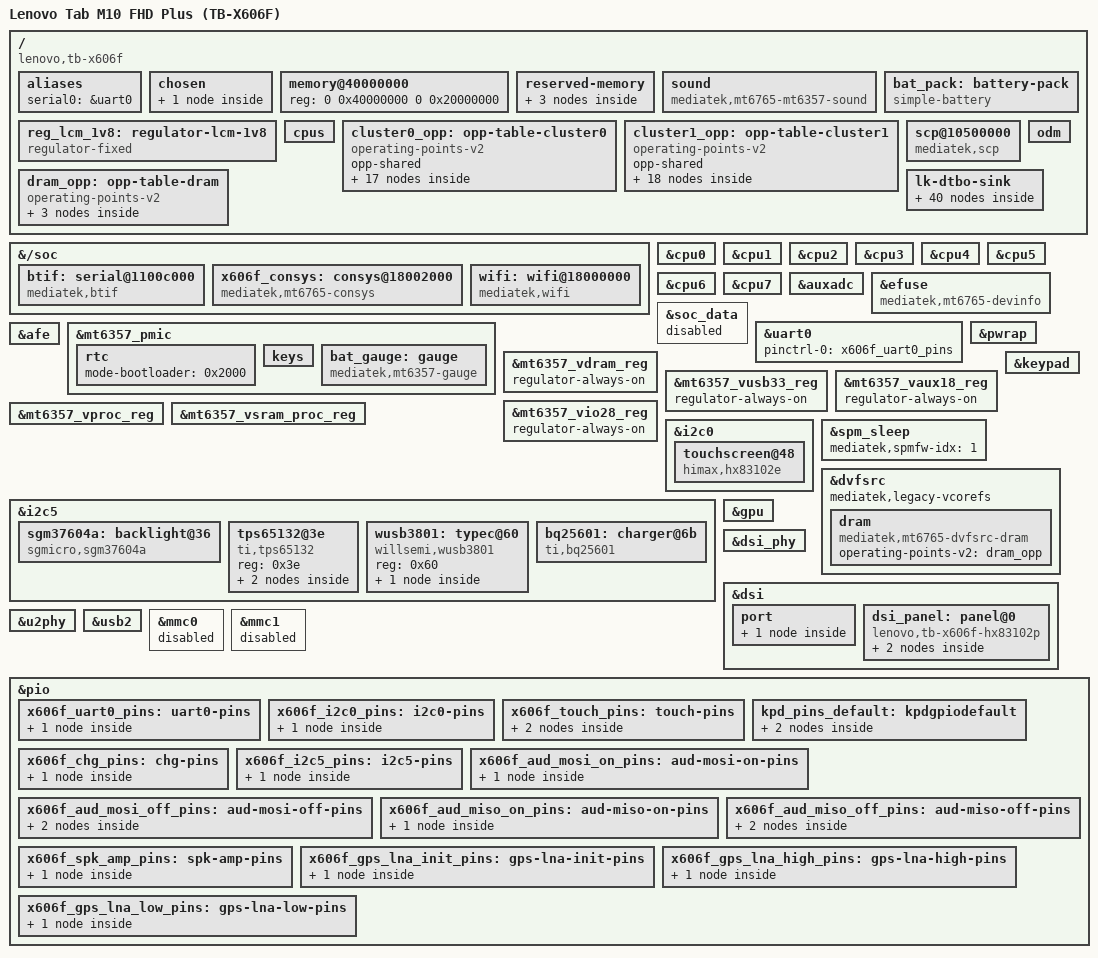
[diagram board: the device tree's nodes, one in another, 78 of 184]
// SPDX-License-Identifier: (GPL-2.0-only OR MIT)
/*
 * Lenovo Tab M10 FHD Plus (TB-X606F / achilles6_row_wifi) DTS.
 * SoC: MT8768WT (MT6765 family) + MT6357 PMIC.
 */

/dts-v1/;

#include <dt-bindings/gpio/gpio.h>
#include <dt-bindings/iio/adc/mediatek,mt6357-auxadc.h>
#include <dt-bindings/input/input.h>
#include <dt-bindings/pinctrl/mediatek,mt6765-pinfunc.h>
#include "mt6765.dtsi"
#include "mt6357.dtsi"

/ {
	model = "Lenovo Tab M10 FHD Plus (TB-X606F)";
	compatible = "lenovo,tb-x606f", "mediatek,mt6765";
	chassis-type = "tablet";

	aliases {
		serial0 = &uart0;
	};

	chosen: chosen {
		#address-cells = <2>;
		#size-cells = <2>;
		ranges;
		bootargs = "console=tty0";
		kaslr-seed = <0x00 0x00>;
		stdout-path = "serial0:921600n8";

		framebuffer0: framebuffer@7dfe0000 {
			compatible = "simple-framebuffer";
			reg = <0x00 0x7dfe0000 0x00 0x1f20000>;
			width = <1200>;
			height = <1920>;
			stride = <4864>;
			format = "a8r8g8b8";
			status = "okay";
		};
	};

	/* LK updates /memory reg at boot. */
	memory@40000000 {
		device_type = "memory";
		reg = <0 0x40000000 0 0x20000000>;
	};

	reserved-memory {
		#address-cells = <2>;
		#size-cells = <2>;
		ranges;

		ramoops@6ff00000 {
			compatible = "ramoops";
			no-map;
			reg = <0 0x6ff00000 0 0xe0000>;
			record-size = <0x40000>;
			console-size = <0x40000>;
			pmsg-size = <0x10000>;
		};

		consys_mem: consys-reserve-memory {
			compatible = "mediatek,consys-reserve-memory";
			no-map;
			size = <0 0x400000>;
			alignment = <0 0x1000000>;
			alloc-ranges = <0 0x40000000 0 0x80000000>;
		};

		wifi_mem: wifi-reserve-memory {
			compatible = "shared-dma-pool";
			no-map;
			size = <0 0x300000>;
			alignment = <0 0x1000000>;
			alloc-ranges = <0 0x40000000 0 0x80000000>;
		};
	};

	sound {
		compatible = "mediatek,mt6765-mt6357-sound";
		model = "lenovo-tb-x606f";
		mediatek,platform = <&afe>;
		mediatek,speaker-enable-gpios = <&pio 151 GPIO_ACTIVE_HIGH>,
						<&pio 153 GPIO_ACTIVE_HIGH>;
		pinctrl-names = "default", "aud_mosi_off", "aud_mosi_on",
				"aud_miso_off", "aud_miso_on";
		pinctrl-0 = <&x606f_spk_amp_pins>;
		pinctrl-1 = <&x606f_aud_mosi_off_pins>;
		pinctrl-2 = <&x606f_aud_mosi_on_pins>;
		pinctrl-3 = <&x606f_aud_miso_off_pins>;
		pinctrl-4 = <&x606f_aud_miso_on_pins>;
	};

	reg_lcm_1v8: regulator-lcm-1v8 {
		compatible = "regulator-fixed";
		regulator-name = "lcm-1v8";
		regulator-min-microvolt = <1800000>;
		regulator-max-microvolt = <1800000>;
		regulator-boot-on;
		regulator-always-on;
	};

	bat_pack: battery-pack {
		compatible = "simple-battery";
		device-chemistry = "lithium-ion";
		charge-full-design-microamp-hours = <5100000>;
		voltage-max-design-microvolt = <4400000>;
		constant-charge-voltage-max-microvolt = <4400000>;
		constant-charge-current-max-microamp = <2040000>;
		precharge-current-microamp = <180000>;
		charge-term-current-microamp = <180000>;
		alert-celsius = <0 50>;
	};

	cpus {
		/delete-node/ idle-states;
	};

	cluster0_opp: opp-table-cluster0 {
		compatible = "operating-points-v2";
		opp-shared;

		opp-900000000 {
			opp-hz = /bits/ 64 <900000000>;
			required-opps = <&dram_opp_low>;
			opp-microvolt = <812500>;
		};

		opp-979000000 {
			opp-hz = /bits/ 64 <979000000>;
			required-opps = <&dram_opp_low>;
			opp-microvolt = <812500>;
		};

		opp-1085000000 {
			opp-hz = /bits/ 64 <1085000000>;
			required-opps = <&dram_opp_low>;
			opp-microvolt = <812500>;
		};

		opp-1218000000 {
			opp-hz = /bits/ 64 <1218000000>;
			required-opps = <&dram_opp_low>;
			opp-microvolt = <812500>;
		};

		opp-1351000000 {
			opp-hz = /bits/ 64 <1351000000>;
			required-opps = <&dram_opp_low>;
			opp-microvolt = <812500>;
		};

		opp-1484000000 {
			opp-hz = /bits/ 64 <1484000000>;
			required-opps = <&dram_opp_low>;
			opp-microvolt = <812500>;
		};

		opp-1617000000 {
			opp-hz = /bits/ 64 <1617000000>;
			required-opps = <&dram_opp_mid>;
			opp-microvolt = <812500>;
		};

		opp-1750000000 {
			opp-hz = /bits/ 64 <1750000000>;
			required-opps = <&dram_opp_high>;
			opp-microvolt = <850000>;
		};

		opp-1803000000 {
			opp-hz = /bits/ 64 <1803000000>;
			required-opps = <&dram_opp_high>;
			opp-microvolt = <893750>;
		};

		opp-1856000000 {
			opp-hz = /bits/ 64 <1856000000>;
			required-opps = <&dram_opp_high>;
			opp-microvolt = <937500>;
		};

		opp-1909000000 {
			opp-hz = /bits/ 64 <1909000000>;
			required-opps = <&dram_opp_high>;
			opp-microvolt = <975000>;
		};

		opp-1962000000 {
			opp-hz = /bits/ 64 <1962000000>;
			required-opps = <&dram_opp_high>;
			opp-microvolt = <1018750>;
		};

		opp-2015000000 {
			opp-hz = /bits/ 64 <2015000000>;
			required-opps = <&dram_opp_high>;
			opp-microvolt = <1056250>;
		};

		opp-2068000000 {
			opp-hz = /bits/ 64 <2068000000>;
			required-opps = <&dram_opp_high>;
			opp-microvolt = <1100000>;
		};

		opp-2130000000 {
			opp-hz = /bits/ 64 <2130000000>;
			required-opps = <&dram_opp_high>;
			opp-microvolt = <1150000>;
		};

		opp-2200000000 {
			opp-hz = /bits/ 64 <2200000000>;
			required-opps = <&dram_opp_high>;
			opp-microvolt = <1200000>;
		};

		opp-2300000000 {
			opp-hz = /bits/ 64 <2300000000>;
			required-opps = <&dram_opp_high>;
			opp-microvolt = <1200000>;
			turbo-mode;
		};
	};

	cluster1_opp: opp-table-cluster1 {
		compatible = "operating-points-v2";
		opp-shared;

		opp-400000000 {
			opp-hz = /bits/ 64 <400000000>;
			required-opps = <&dram_opp_low>;
			opp-microvolt = <812500>;
		};

		opp-501000000 {
			opp-hz = /bits/ 64 <501000000>;
			required-opps = <&dram_opp_low>;
			opp-microvolt = <812500>;
		};

		opp-542000000 {
			opp-hz = /bits/ 64 <542000000>;
			required-opps = <&dram_opp_low>;
			opp-microvolt = <812500>;
		};

		opp-643000000 {
			opp-hz = /bits/ 64 <643000000>;
			required-opps = <&dram_opp_low>;
			opp-microvolt = <812500>;
		};

		opp-745000000 {
			opp-hz = /bits/ 64 <745000000>;
			required-opps = <&dram_opp_low>;
			opp-microvolt = <812500>;
		};

		opp-846000000 {
			opp-hz = /bits/ 64 <846000000>;
			required-opps = <&dram_opp_low>;
			opp-microvolt = <812500>;
		};

		opp-948000000 {
			opp-hz = /bits/ 64 <948000000>;
			required-opps = <&dram_opp_low>;
			opp-microvolt = <812500>;
		};

		opp-1050000000 {
			opp-hz = /bits/ 64 <1050000000>;
			required-opps = <&dram_opp_low>;
			opp-microvolt = <850000>;
		};

		opp-1114000000 {
			opp-hz = /bits/ 64 <1114000000>;
			required-opps = <&dram_opp_low>;
			opp-microvolt = <893750>;
		};

		opp-1179000000 {
			opp-hz = /bits/ 64 <1179000000>;
			required-opps = <&dram_opp_low>;
			opp-microvolt = <937500>;
		};

		opp-1244000000 {
			opp-hz = /bits/ 64 <1244000000>;
			required-opps = <&dram_opp_low>;
			opp-microvolt = <975000>;
		};

		opp-1309000000 {
			opp-hz = /bits/ 64 <1309000000>;
			required-opps = <&dram_opp_mid>;
			opp-microvolt = <1018750>;
		};

		opp-1374000000 {
			opp-hz = /bits/ 64 <1374000000>;
			required-opps = <&dram_opp_mid>;
			opp-microvolt = <1056250>;
		};

		opp-1439000000 {
			opp-hz = /bits/ 64 <1439000000>;
			required-opps = <&dram_opp_mid>;
			opp-microvolt = <1100000>;
		};

		opp-1515000000 {
			opp-hz = /bits/ 64 <1515000000>;
			required-opps = <&dram_opp_mid>;
			opp-microvolt = <1150000>;
		};

		opp-1600000000 {
			opp-hz = /bits/ 64 <1600000000>;
			required-opps = <&dram_opp_high>;
			opp-microvolt = <1200000>;
		};

		opp-1700000000 {
			opp-hz = /bits/ 64 <1700000000>;
			required-opps = <&dram_opp_high>;
			opp-microvolt = <1200000>;
			turbo-mode;
		};

		opp-1800000000 {
			opp-hz = /bits/ 64 <1800000000>;
			required-opps = <&dram_opp_high>;
			opp-microvolt = <1200000>;
			turbo-mode;
		};
	};

	dram_opp: opp-table-dram {
		compatible = "operating-points-v2";

		dram_opp_low: opp-1534000000 {
			opp-hz = /bits/ 64 <1534000000>;
			opp-level = <0>;
			opp-suspend;
		};

		dram_opp_mid: opp-2392000000 {
			opp-hz = /bits/ 64 <2392000000>;
			opp-level = <3>;
		};

		dram_opp_high: opp-3200000000 {
			opp-hz = /bits/ 64 <3200000000>;
			opp-level = <5>;
		};
	};

	/* Stock LK checks for mediatek,scp and scp_sramSize before booting. */
	scp@10500000 {
		compatible = "mediatek,scp";
		status = "okay";
		core_1 = "enable";
		scp_sramSize = <0x40000>;
	};

	/* Stock LK leds_init() looks up /odm/led@0..6; omit simple-bus so Linux does not probe vendor children. */
	odm: odm { };

	/*
	 * Stock LK asserts ufdt_apply_overlay() on the on-device dtbo[0] partition.
	 * Provide __symbols__ targets for all 4.19/vendor labels referenced by dtbo[0]
	 * inside a non-bus sink node so Linux ignores them.
	 */
	lk-dtbo-sink {
		reserved_memory: reserved-memory-sink { };
		regulator_vibrator: regulator-vibrator { };
		mt_pmic_vibr_ldo_reg: mt-pmic-vibr-ldo-reg { };
		touch: touch { };
		charger: charger { };
		consys: consys { };
		accdet: accdet { };
		irtx_pwm: irtx-pwm { };
		audgpio: audgpio { };
		mtkfb: mtkfb { };
		mtk_charger_type: mtk-charger-type { };
		camera_af_hw_node: camera-af-hw-node { };
		mt_pmic_vldo28_ldo_reg: mt-pmic-vldo28-ldo-reg { };
		mtk_gauge: mtk-gauge { };
		pe: pe { };
		pe2: pe2 { };
		pe4: pe4 { };
		pdc: pdc { };
		usb: usb { };
		toprgu: toprgu { };
		pd_adapter: pd-adapter { };
		pmic_clock_buffer_ctrl: pmic-clock-buffer-ctrl { };
		i2c7: i2c7 { };
		i2c8: i2c8 { };
		i2c9: i2c9 { };
		gpio_usage_mapping: gpio-usage-mapping { };
		gpio: gpio { };
		msdc1_ins: msdc1-ins { };
		otg_iddig: otg-iddig { };
		dsi_te: dsi-te { };
		main_pmic: main-pmic { };
		md1_sim1_hot_plug_eint: md1-sim1-hot-plug-eint { };
		md1_sim2_hot_plug_eint: md1-sim2-hot-plug-eint { };
		mt_pmic_vcama_ldo_reg: mt-pmic-vcama-ldo-reg { };
		mt_pmic_vsim1_ldo_reg: mt-pmic-vsim1-ldo-reg { };
		mt_pmic_vsim2_ldo_reg: mt-pmic-vsim2-ldo-reg { };
		mt_pmic_vcamd_ldo_reg: mt-pmic-vcamd-ldo-reg { };
		mt_pmic_vcamio_ldo_reg: mt-pmic-vcamio-ldo-reg { };
		kd_camera_hw1: kd-camera-hw1 { };
		msdc1: msdc1 { };
	};
};

/*
 * Connectivity (CONSYS Wi-Fi/BT/GPS). The Linux node uses label x606f_consys
 * because lk-dtbo-sink holds the legacy "consys" label targeted by dtbo[0].
 */
&{/soc} {
	btif: serial@1100c000 {
		compatible = "mediatek,btif";
		reg = <0 0x1100c000 0 0x1000>,
		      <0 0x11000880 0 0x80>,
		      <0 0x11000900 0 0x80>;
		interrupts = <GIC_SPI 112 IRQ_TYPE_LEVEL_LOW>,
			     <GIC_SPI 132 IRQ_TYPE_LEVEL_LOW>,
			     <GIC_SPI 133 IRQ_TYPE_LEVEL_LOW>;
		clocks = <&infracfg CLK_IFR_BTIF>,
			 <&infracfg CLK_IFR_AP_DMA>;
		clock-names = "btifc", "apdmac";
	};

	x606f_consys: consys@18002000 {
		compatible = "mediatek,mt6765-consys";
		reg = <0 0x18002000 0 0x1000>,
		      <0 0x10007000 0 0x100>,
		      <0 0x10001000 0 0x1000>,
		      <0 0x10006000 0 0x1000>,
		      <0 0x18007000 0 0x1000>,
		      <0 0x180b1000 0 0x1000>,
		      <0 0x180a3000 0 0x1000>,
		      <0 0x180a5000 0 0x800>,
		      <0 0x180c1000 0 0x1000>,
		      <0 0x18004000 0 0x1000>,
		      <0 0 0 0>,
		      <0 0x1020e000 0 0x1000>,
		      <0 0x1020e000 0 0x1000>;
		interrupts = <GIC_SPI 267 IRQ_TYPE_LEVEL_LOW>,
			     <GIC_SPI 269 IRQ_TYPE_LEVEL_LOW>,
			     <GIC_SPI 270 IRQ_TYPE_EDGE_RISING>;
		power-domains = <&spm MT6765_POWER_DOMAIN_CONN>;
		memory-region = <&consys_mem>;
		pinctrl-names = "default", "gps_lna_state_init",
				"gps_lna_state_oh", "gps_lna_state_ol";
		pinctrl-0 = <&x606f_gps_lna_init_pins>;
		pinctrl-1 = <&x606f_gps_lna_init_pins>;
		pinctrl-2 = <&x606f_gps_lna_high_pins>;
		pinctrl-3 = <&x606f_gps_lna_low_pins>;
		pmic = <&mt6357_pmic>;
		vcn18-supply = <&mt6357_vcn18_reg>;
		vcn28-supply = <&mt6357_vcn28_reg>;
		vcn33_bt-supply = <&mt6357_vcn33_bt_reg>;
		vcn33_wifi-supply = <&mt6357_vcn33_wifi_reg>;
	};

	wifi: wifi@18000000 {
		compatible = "mediatek,wifi";
		reg = <0 0x18000000 0 0x100000>;
		interrupts = <GIC_SPI 268 IRQ_TYPE_LEVEL_LOW>;
		memory-region = <&wifi_mem>;
	};
};

&cpu0 {
	clocks = <&mcucfg CLK_MCU_MP0_SEL>,
		 <&topckgen CLK_TOP_ARMPLL_DIVIDER_PLL1_EN>;
	clock-names = "cpu", "intermediate";
	operating-points-v2 = <&cluster0_opp>;
	proc-supply = <&mt6357_vproc_reg>;
	sram-supply = <&mt6357_vsram_proc_reg>;
	/delete-property/ cpu-idle-states;
};

&cpu1 {
	clocks = <&mcucfg CLK_MCU_MP0_SEL>,
		 <&topckgen CLK_TOP_ARMPLL_DIVIDER_PLL1_EN>;
	clock-names = "cpu", "intermediate";
	operating-points-v2 = <&cluster0_opp>;
	proc-supply = <&mt6357_vproc_reg>;
	sram-supply = <&mt6357_vsram_proc_reg>;
	/delete-property/ cpu-idle-states;
};

&cpu2 {
	clocks = <&mcucfg CLK_MCU_MP0_SEL>,
		 <&topckgen CLK_TOP_ARMPLL_DIVIDER_PLL1_EN>;
	clock-names = "cpu", "intermediate";
	operating-points-v2 = <&cluster0_opp>;
	proc-supply = <&mt6357_vproc_reg>;
	sram-supply = <&mt6357_vsram_proc_reg>;
	/delete-property/ cpu-idle-states;
};

&cpu3 {
	clocks = <&mcucfg CLK_MCU_MP0_SEL>,
		 <&topckgen CLK_TOP_ARMPLL_DIVIDER_PLL1_EN>;
	clock-names = "cpu", "intermediate";
	operating-points-v2 = <&cluster0_opp>;
	proc-supply = <&mt6357_vproc_reg>;
	sram-supply = <&mt6357_vsram_proc_reg>;
	/delete-property/ cpu-idle-states;
};

&cpu4 {
	clocks = <&mcucfg CLK_MCU_MP1_SEL>,
		 <&topckgen CLK_TOP_ARMPLL_DIVIDER_PLL1_EN>;
	clock-names = "cpu", "intermediate";
	operating-points-v2 = <&cluster1_opp>;
	proc-supply = <&mt6357_vproc_reg>;
	sram-supply = <&mt6357_vsram_proc_reg>;
	/delete-property/ cpu-idle-states;
};

&cpu5 {
	clocks = <&mcucfg CLK_MCU_MP1_SEL>,
		 <&topckgen CLK_TOP_ARMPLL_DIVIDER_PLL1_EN>;
	clock-names = "cpu", "intermediate";
	operating-points-v2 = <&cluster1_opp>;
	proc-supply = <&mt6357_vproc_reg>;
	sram-supply = <&mt6357_vsram_proc_reg>;
	/delete-property/ cpu-idle-states;
};

&cpu6 {
	clocks = <&mcucfg CLK_MCU_MP1_SEL>,
		 <&topckgen CLK_TOP_ARMPLL_DIVIDER_PLL1_EN>;
	clock-names = "cpu", "intermediate";
	operating-points-v2 = <&cluster1_opp>;
	proc-supply = <&mt6357_vproc_reg>;
	sram-supply = <&mt6357_vsram_proc_reg>;
	/delete-property/ cpu-idle-states;
};

&cpu7 {
	clocks = <&mcucfg CLK_MCU_MP1_SEL>,
		 <&topckgen CLK_TOP_ARMPLL_DIVIDER_PLL1_EN>;
	clock-names = "cpu", "intermediate";
	operating-points-v2 = <&cluster1_opp>;
	proc-supply = <&mt6357_vproc_reg>;
	sram-supply = <&mt6357_vsram_proc_reg>;
	/delete-property/ cpu-idle-states;
};

&auxadc {
	status = "okay";
};

&efuse {
	compatible = "mediatek,mt6765-devinfo";
};

&soc_data {
	status = "disabled";
};


&uart0 {
	pinctrl-names = "default";
	pinctrl-0 = <&x606f_uart0_pins>;
	status = "okay";
};

&pwrap {
	status = "okay";
};

&afe {
	status = "okay";
};

&mt6357_pmic {
	interrupt-controller;
	interrupt-parent = <&pio>;
	interrupts = <144 IRQ_TYPE_LEVEL_HIGH>;
	#interrupt-cells = <2>;

	rtc {
		mode-bootloader = <0x2000>;
	};

	keys {
		mediatek,long-press-mode = <1>;
		power-off-time-sec = <0>;

		/delete-node/ key-home;
	};

	bat_gauge: gauge {
		compatible = "mediatek,mt6357-gauge";
		power-supplies = <&bq25601>;
		monitored-battery = <&bat_pack>;
		shunt-resistor-micro-ohms = <10000>;
		mediatek,current-gain-permille = <1000>;
		io-channels = <&pmic_adc MT6357_AUXADC_ISENSE>,
			      <&pmic_adc MT6357_AUXADC_BAT_TEMP>,
			      <&pmic_adc MT6357_AUXADC_VBIF>;
		io-channel-names = "battery-voltage", "battery-thermistor", "thermistor-reference";
		mediatek,thermistor-pullup-ohms = <16900>;
		mediatek,thermistor-series-micro-ohms = <10000>;
		mediatek,thermistor-resistance-table =
			<(-40000) 195652>, <(-35000) 148171>, <(-30000) 113347>,
			<(-25000) 87559>, <(-20000) 68237>, <(-15000) 53650>,
			<(-10000) 42506>, <(-5000) 33892>, <0 27219>,
			<5000 22021>, <10000 17926>, <15000 14674>,
			<20000 12081>, <25000 10000>, <30000 8315>,
			<35000 6948>, <40000 5834>, <45000 4917>,
			<50000 4161>, <55000 3535>, <60000 3014>;
	};
};

&mt6357_vdram_reg {
	regulator-always-on;
};

&mt6357_vusb33_reg {
	regulator-always-on;
};

&mt6357_vaux18_reg {
	regulator-always-on;
};

&mt6357_vio28_reg {
	regulator-always-on;
};

&mt6357_vproc_reg {
	regulator-min-microvolt = <800000>;
	regulator-max-microvolt = <1200000>;
};

&mt6357_vsram_proc_reg {
	regulator-min-microvolt = <900000>;
	regulator-max-microvolt = <1200000>;
};

&keypad {
	keypad,num-rows = <1>;
	keypad,num-columns = <2>;
	linux,keymap = <MATRIX_KEY(0, 0, KEY_VOLUMEUP)
			MATRIX_KEY(0, 1, KEY_VOLUMEDOWN)>;
	debounce-delay-ms = <32>;
	wakeup-source;
	status = "okay";
};

&i2c0 {
	pinctrl-names = "default";
	pinctrl-0 = <&x606f_i2c0_pins>;
	clock-frequency = <400000>;
	mediatek,use-push-pull;
	status = "okay";

	touchscreen@48 {
		compatible = "himax,hx83102e";
		reg = <0x48>;
		pinctrl-names = "default";
		pinctrl-0 = <&x606f_touch_pins>;
		interrupt-parent = <&pio>;
		interrupts = <10 IRQ_TYPE_LEVEL_LOW>;
		reset-gpios = <&pio 172 GPIO_ACTIVE_LOW>;
		vdd-supply = <&mt6357_vldo28_reg>;
		panel = <&dsi_panel>;
		touchscreen-size-x = <1200>;
		touchscreen-size-y = <1920>;
	};
};

&i2c5 {
	pinctrl-names = "default";
	pinctrl-0 = <&x606f_i2c5_pins>;
	clock-frequency = <400000>;
	mediatek,use-open-drain;
	status = "okay";

	sgm37604a: backlight@36 {
		compatible = "sgmicro,sgm37604a";
		reg = <0x36>;
		enable-gpios = <&pio 154 GPIO_ACTIVE_HIGH>;
		default-brightness-level = <3072>;
	};

	tps65132@3e {
		compatible = "ti,tps65132";
		reg = <0x3e>;

		reg_lcd_avdd: outp {
			regulator-name = "lcd-avdd";
			regulator-min-microvolt = <6000000>;
			regulator-max-microvolt = <6000000>;
			regulator-boot-on;
			enable-gpios = <&pio 167 GPIO_ACTIVE_HIGH>;
		};

		reg_lcd_avee: outn {
			regulator-name = "lcd-avee";
			regulator-min-microvolt = <6000000>;
			regulator-max-microvolt = <6000000>;
			regulator-boot-on;
			enable-gpios = <&pio 168 GPIO_ACTIVE_HIGH>;
		};
	};

	wusb3801: typec@60 {
		compatible = "willsemi,wusb3801";
		reg = <0x60>;

		connector {
			compatible = "usb-c-connector";
			label = "USB-C";
			power-role = "dual";
			try-power-role = "sink";
			data-role = "dual";
			typec-power-opmode = "default";
		};
	};

	bq25601: charger@6b {
		compatible = "ti,bq25601";
		reg = <0x6b>;
		pinctrl-names = "default";
		pinctrl-0 = <&x606f_chg_pins>;
		interrupt-parent = <&pio>;
		interrupts = <2 IRQ_TYPE_EDGE_FALLING>;
		monitored-battery = <&bat_pack>;
		input-current-limit-microamp = <2000000>;
		input-voltage-limit-microvolt = <4500000>;
	};
};

&spm_sleep {
	mediatek,spmfw-idx = <1>;
	status = "okay";
};

&dvfsrc {
	mediatek,legacy-vcorefs;

	dram {
		compatible = "mediatek,mt6765-dvfsrc-dram";
		operating-points-v2 = <&dram_opp>;
	};
};

&gpu {
	vcore-supply = <&mt6357_vcore_reg>;
	dvfsrc-vcore-supply = <&dvfsrc_vcore>;
	status = "okay";
};

&dsi_phy {
	status = "okay";
};

&dsi {
	status = "okay";

	port {
		dsi_out: endpoint {
			remote-endpoint = <&panel_in>;
		};
	};

	dsi_panel: panel@0 {
		compatible = "lenovo,tb-x606f-hx83102p", "himax,hx83102";
		reg = <0>;
		enable-gpios = <&pio 45 GPIO_ACTIVE_HIGH>;
		pp1800-supply = <&reg_lcm_1v8>;
		avdd-supply = <&reg_lcd_avdd>;
		avee-supply = <&reg_lcd_avee>;
		backlight = <&sgm37604a>;

		port {
			panel_in: endpoint {
				remote-endpoint = <&dsi_out>;
			};
		};
	};
};

&u2phy {
	status = "okay";
};

&usb2 {
	assigned-clocks = <&topckgen CLK_TOP_USB_TOP_SEL>;
	assigned-clock-parents = <&topckgen CLK_TOP_UNIVPLL3_D4>;
	dr_mode = "peripheral";
	maximum-speed = "high-speed";
	status = "okay";
};

/* Stage 2: keep internal eMMC and SD card disabled until display is verified. */
&mmc0 {
	status = "disabled";
};

&mmc1 {
	status = "disabled";
};

&pio {
	x606f_uart0_pins: uart0-pins {
		pins {
			pinmux = <PINMUX_GPIO95__FUNC_URXD0>,
				 <PINMUX_GPIO96__FUNC_UTXD0>;
		};
	};
	x606f_i2c0_pins: i2c0-pins {
		pins {
			pinmux = <PINMUX_GPIO82__FUNC_SDA0>,
				 <PINMUX_GPIO83__FUNC_SCL0>;
			input-enable;
			bias-pull-up;
		};
	};
	x606f_touch_pins: touch-pins {
		pins-irq {
			pinmux = <PINMUX_GPIO10__FUNC_GPIO10>;
			input-enable;
			bias-disable;
		};
		pins-reset {
			pinmux = <PINMUX_GPIO172__FUNC_GPIO172>;
		};
	};
	kpd_pins_default: kpdgpiodefault {
		pins-rows {
			pinmux = <PINMUX_GPIO92__FUNC_KPROW0>;
			output-low;
			bias-disable;
		};
		pins-cols {
			pinmux = <PINMUX_GPIO93__FUNC_KPCOL0>,
				 <PINMUX_GPIO94__FUNC_KPCOL1>;
			input-enable;
			input-schmitt-enable;
			bias-pull-up = <MTK_PUPD_SET_R1R0_10>;
		};
	};
	x606f_chg_pins: chg-pins {
		pins {
			pinmux = <PINMUX_GPIO2__FUNC_GPIO2>;
			input-enable;
			bias-pull-up;
		};
	};
	x606f_i2c5_pins: i2c5-pins {
		pins {
			pinmux = <PINMUX_GPIO48__FUNC_SCL5>,
				 <PINMUX_GPIO49__FUNC_SDA5>;
			bias-pull-up;
		};
	};
	x606f_aud_mosi_on_pins: aud-mosi-on-pins {
		pins-aud {
			pinmux = <PINMUX_GPIO136__FUNC_AUD_CLK_MOSI>,
				 <PINMUX_GPIO137__FUNC_AUD_SYNC_MOSI>,
				 <PINMUX_GPIO138__FUNC_AUD_DAT_MOSI0>,
				 <PINMUX_GPIO139__FUNC_AUD_DAT_MOSI1>;
		};
	};
	x606f_aud_mosi_off_pins: aud-mosi-off-pins {
		pins-clk {
			pinmux = <PINMUX_GPIO136__FUNC_GPIO136>;
		};
		pins-dat {
			pinmux = <PINMUX_GPIO138__FUNC_GPIO138>,
				 <PINMUX_GPIO139__FUNC_GPIO139>;
			input-enable;
			bias-disable;
		};
	};
	x606f_aud_miso_on_pins: aud-miso-on-pins {
		pins-aud {
			pinmux = <PINMUX_GPIO140__FUNC_AUD_CLK_MISO>,
				 <PINMUX_GPIO141__FUNC_AUD_SYNC_MISO>,
				 <PINMUX_GPIO142__FUNC_AUD_DAT_MISO0>,
				 <PINMUX_GPIO143__FUNC_AUD_DAT_MISO1>;
		};
	};
	x606f_aud_miso_off_pins: aud-miso-off-pins {
		pins-clk {
			pinmux = <PINMUX_GPIO140__FUNC_GPIO140>;
		};
		pins-dat {
			pinmux = <PINMUX_GPIO142__FUNC_GPIO142>,
				 <PINMUX_GPIO143__FUNC_GPIO143>;
			input-enable;
			bias-disable;
		};
	};
	x606f_spk_amp_pins: spk-amp-pins {
		pins-amp {
			pinmux = <PINMUX_GPIO151__FUNC_GPIO151>,
				 <PINMUX_GPIO153__FUNC_GPIO153>;
			output-low;
		};
	};
	x606f_gps_lna_init_pins: gps-lna-init-pins {
		pins-lna {
			pinmux = <PINMUX_GPIO91__FUNC_GPIO91>;
			bias-disable;
			output-low;
		};
	};
	x606f_gps_lna_high_pins: gps-lna-high-pins {
		pins-lna {
			pinmux = <PINMUX_GPIO91__FUNC_GPIO91>;
			output-high;
		};
	};
	x606f_gps_lna_low_pins: gps-lna-low-pins {
		pins-lna {
			pinmux = <PINMUX_GPIO91__FUNC_GPIO91>;
			output-low;
		};
	};
};
